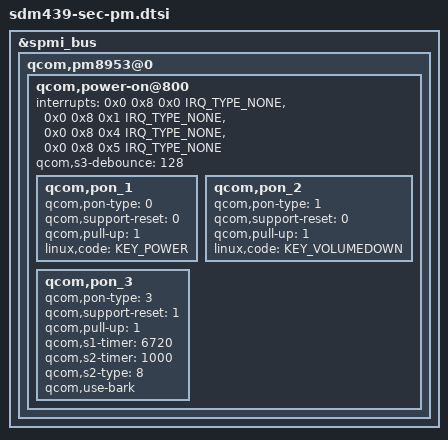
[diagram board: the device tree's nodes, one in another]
#include <dt-bindings/input/linux-event-codes.h>

&spmi_bus {
	qcom,pm8953@0 {
		qcom,power-on@800 {
			interrupts = <0x0 0x8 0x0 IRQ_TYPE_NONE>,
				     <0x0 0x8 0x1 IRQ_TYPE_NONE>,
					 <0x0 0x8 0x4 IRQ_TYPE_NONE>,
				     <0x0 0x8 0x5 IRQ_TYPE_NONE>;
			interrupt-names = "kpdpwr", "resin",
                    "resin-bark", "kpdpwr-resin-bark";

			qcom,s3-debounce = <128>;
			qcom,pon_1 {
				qcom,pon-type = <0>;	/* PON_POWER_ON_TYPE_KPDPWR */
				qcom,support-reset = <0>;
				qcom,pull-up = <1>;
				linux,code = <KEY_POWER>;
			};

			qcom,pon_2 {
				qcom,pon-type = <1>;	/* PON_POWER_ON_TYPE_RESIN */
				qcom,support-reset = <0>;
				qcom,pull-up = <1>;
				linux,code = <KEY_VOLUMEDOWN>;
			};

			qcom,pon_3 {
				qcom,pon-type = <3>;	/* PON_POWER_ON_TYPE_KPDPWR_RESIN */
				qcom,support-reset = <1>;
				qcom,pull-up = <1>;
				qcom,s1-timer = <6720>;
				qcom,s2-timer = <1000>;
				qcom,s2-type = <8>;
				qcom,use-bark;
			};
		};
	};
};
